AUTOSAR XML (schema 00052)
package /apd/AdaptiveApplicationSwComponentTypes
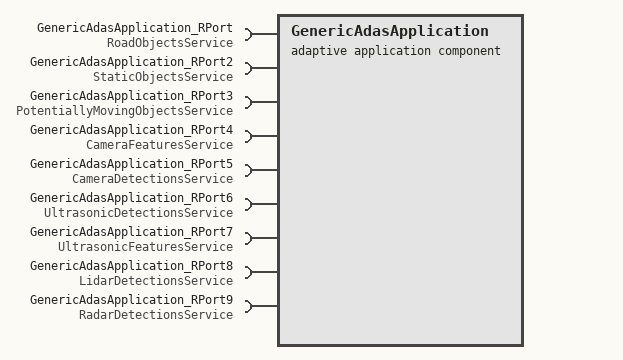
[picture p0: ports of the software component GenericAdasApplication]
  adaptive application sw component type GenericAdasApplication
    9 x require port:
      GenericAdasApplication_RPort: required-interface=RoadObjectsService
      GenericAdasApplication_RPort2: required-interface=StaticObjectsService
      GenericAdasApplication_RPort3: required-interface=PotentiallyMovingObjectsService
      GenericAdasApplication_RPort4: required-interface=CameraFeaturesService
      GenericAdasApplication_RPort5: required-interface=CameraDetectionsService
      GenericAdasApplication_RPort6: required-interface=UltrasonicDetectionsService
      GenericAdasApplication_RPort7: required-interface=UltrasonicFeaturesService
      GenericAdasApplication_RPort8: required-interface=LidarDetectionsService
      GenericAdasApplication_RPort9: required-interface=RadarDetectionsService
package /apd/Executables
  executable GenericAdasApplication: category=APPLICATION_LEVEL, minimum-timer-granularity=1000.0
    root sw component prototype GenericAdasApplication: application-type=GenericAdasApplication
